# ADSP-2183xW_HPC register map
Vendor: Analog Devices; Series: ADSP-2183xW_HPC; File version: 3.0.3.517
CPU: 
Registers are 32-bit, read-write, reset 0x0 unless marked. A register's access mark holds for its fields unless they carry their own. Offsets are from the block's base; [hi:lo] are bit positions; {n}, {i} and the like mark numbered series; 'fields as' and 'values as' point back to an identical list.

## PFB0 — Prefetch buffer mmr
Base 0x31076000
Same registers: PFB1 0x31145000, PFB2 0x31149000
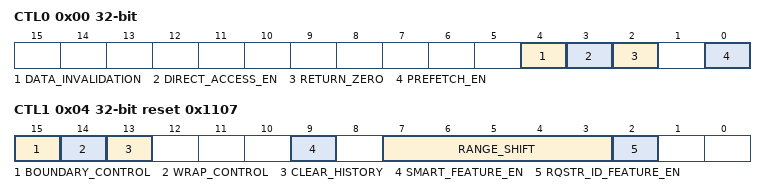
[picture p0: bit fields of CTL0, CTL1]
0x00 CTL0 — Control Register 0
  [4] DATA_INVALIDATION — Data Invalid
  [3] DIRECT_ACCESS_EN — Direct Access Enable
  [2] RETURN_ZERO — Return Zero Data
  [0] PREFETCH_EN — Prefetch Enable
0x04 CTL1 reset 0x1107 — Control Register 1
  [15] BOUNDARY_CONTROL range 0x00000000..0x00000001 — 1: Fetch and Prefetch at 4K boundary crossing control. Configure BCR_START, BCR_END for range. 0: Fetch and Prefetch not at 4k boundary.
  [14] WRAP_CONTROL range 0x00000000..0x00000001 — 1: Direct access for WRAP transaction. 0: normal access
  [13] CLEAR_HISTORY range 0x00000000..0x00000001 — Clear addresses history information in SMART feature
  [9] SMART_FEATURE_EN — Smart Feature Enable
  [7:3] RANGE_SHIFT range 0x00000000..0x0000001F
  [2] RQSTR_ID_FEATURE_EN — ID Based Direct Access Enable
0x14 ZERO_START — Return Zero Start Address Register
  [31:0] VAL range 0x00000000..0xFFFFFFFF — Return Zero Start Address
0x18 ZERO_END — Return Zero End Address Register
  [31:0] VAL range 0x00000000..0xFFFFFFFF — Return Zero End Address
0x1C RANGE_SELECT reset 0xFFFF
  [15:0] VAL range 0x00000000..0x0000FFFF — Range select bit selection
0x20 STS0 reset 0x2 — Prefetch Buffer First Status Register
  [1] PFB_IDLE ro — Prefetch Idle
0x50 RQSTR_ID_EN reset 0xF — Requester ID Enable Register
  [3:0] VAL range 0x00000000..0x0000000F — Requester ID Enable
0x54 RQSTR0_ID reset 0xF — Requester ID 0 Register
  [12:0] VAL range 0x00000000..0x00001FFF — Requester Zero ID
0x58 RQSTR0_ID_MSK — Requester ID 0 Mask Register
  [12:0] VAL range 0x00000000..0x00001FFF — Requester Zero ID Mask
0x5C RQSTR1_ID reset 0xF — Requester ID 1 Register
  [12:0] VAL range 0x00000000..0x00001FFF — Requester One ID
0x60 RQSTR1_ID_MSK — Requester ID 1 Mask Register
  [12:0] VAL range 0x00000000..0x00001FFF — Requester One ID Mask
0x64 RQSTR2_ID reset 0xF — Requester ID 2 Register
  [12:0] VAL range 0x00000000..0x00001FFF — Requester Two ID
0x68 RQSTR2_ID_MSK — Requester ID 2 Mask Register
  [12:0] VAL range 0x00000000..0x00001FFF — Requester Two ID Mask
0x6C RQSTR3_ID reset 0xF — Requester ID 3 Register
  [12:0] VAL range 0x00000000..0x00001FFF — Requester Three ID
0x70 RQSTR3_ID_MSK — Requester ID 3 Mask Register
  [12:0] VAL range 0x00000000..0x00001FFF — Requester Three ID Mask

## L2CTL0 — L2 Memory Controller
Base 0x31080000
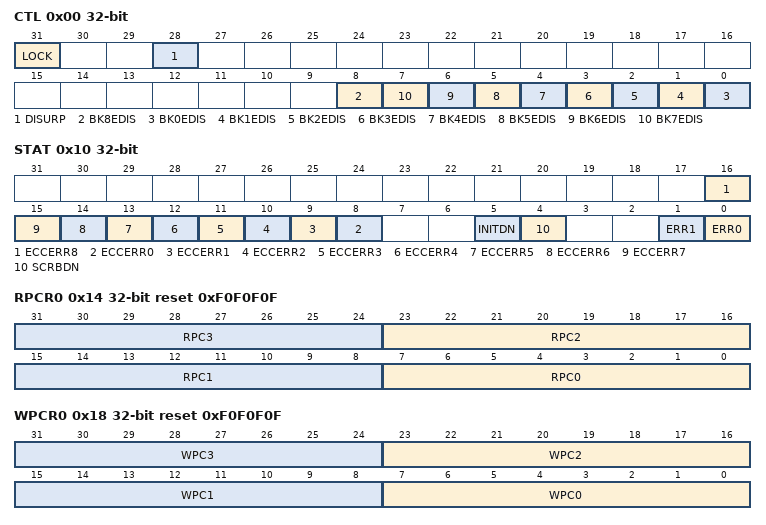
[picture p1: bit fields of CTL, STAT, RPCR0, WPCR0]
0x00 CTL — Control Register
  [31] LOCK
  [28] DISURP — Disable Urgent Request Priority
  [8] BK8EDIS — Bank 8 (ROM) ECC Disable
  [n] BK{n}EDIS (n=0..7) — Bank {n} ECC Disable
0x10 STAT — Status Register
  [16] ECCERR8 — ECC Error Bank 8 (ROM)
  [n+8] ECCERR{n} (n=0..7) — ECC Error Bank {n}
  [5] INITDN — Initialization Status
  [4] SCRBDN — Scrub Status
  [1] ERR1 — Error Port 1
  [0] ERR0 — Error Port 0
0x14 RPCR0 reset 0xF0F0F0F — Read Priority Count Register
  [8n+7:8n] RPC{n} range 0x00000000..0x000000FF (n=0..3) — Read Priority Count {n}
0x18 WPCR0 reset 0xF0F0F0F — Write Priority Count Register
  [8n+7:8n] WPC{n} range 0x00000000..0x000000FF (n=0..3) — Write Priority Count {n}
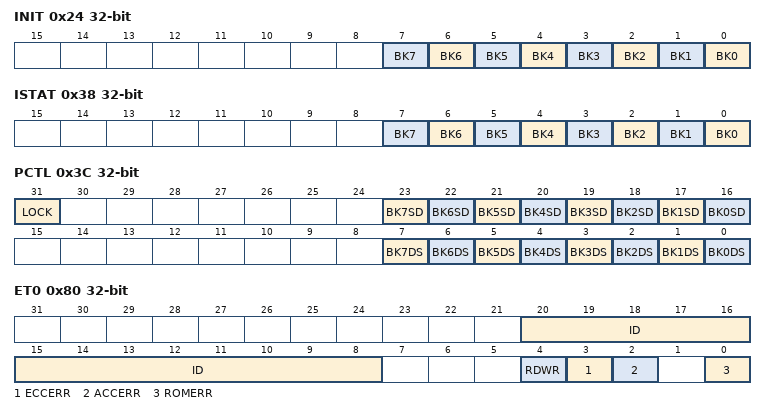
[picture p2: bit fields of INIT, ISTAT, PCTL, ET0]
0x24 INIT — Initialization Register
  [n] BK{n} range 0x00000000..0x00000001 (n=0..7) — Initialize Bank {n}
0x38 ISTAT — Initialization Status Register
  [n] BK{n} ro (n=0..7) — Bank {n} Initialization Status
0x3C PCTL — Power Control Register
  [31] LOCK
  [n+16] BK{n}SD range 0x00000000..0x00000001 (n=0..7) — Bank {n} Shut Down Enable
  [n] BK{n}DS range 0x00000000..0x00000001 (n=0..7) — Bank {n} Deep Sleep Enable
0x40 ERRADDR0 reset 0x20000000 — ECC Error Address 0 Register
  [31:0] VALUE ro — ERRADDR Value
0x44 ERRADDR1 reset 0x20040000 — ECC Error Address 1 Register
  [31:0] VALUE ro — ERRADDR Value
0x48 ERRADDR2 reset 0x20080000 — ECC Error Address 2 Register
  [31:0] VALUE ro — ERRADDR Value
0x4C ERRADDR3 reset 0x200C0000 — ECC Error Address 3 Register
  [31:0] VALUE ro — ERRADDR Value
0x50 ERRADDR4 reset 0x20100000 — ECC Error Address 4 Register
  [31:0] VALUE ro — ERRADDR Value
0x54 ERRADDR5 reset 0x20140000 — ECC Error Address 5 Register
  [31:0] VALUE ro — ERRADDR Value
0x58 ERRADDR6 reset 0x20180000 — ECC Error Address 6 Register
  [31:0] VALUE ro — ERRADDR Value
0x5C ERRADDR7 reset 0x201C0000 — ECC Error Address 7 Register
  [31:0] VALUE ro — ERRADDR Value
0x60 ERRADDR8 reset 0x20200000 — ECC Error Address 8 Register
  [31:0] VALUE ro — ERRADDR Value
0x80 ET0 — Error Type 0 Register
  [20:8] ID ro — Error ID
  [4] RDWR ro — Read/Write Error
  [3] ECCERR ro — ECC Error
  [2] ACCERR ro — Access Error
  [0] ROMERR ro — ROM Error
0x84 EADDR0 — Error Type 0 Address Register
  [31:0] VALUE ro — ERRADDR Value
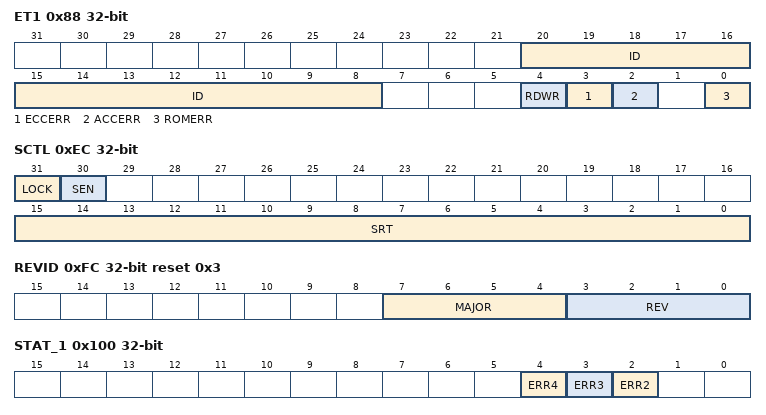
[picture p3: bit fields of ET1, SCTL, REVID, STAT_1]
0x88 ET1 — Error Type 1 Register
  fields as ET0
0x8C EADDR1 — Error Type 1 Address Register
  [31:0] VALUE ro — ERRADDR Value
0xEC SCTL — Scrub Control Register
  [31] LOCK
  [30] SEN range 0x00000000..0x00000001 — Scrub Enable
  [15:0] SRT range 0x00000000..0x0000FFFF — Scrub Rate
0xF0 SADR — Scrub Start Address Register
  [31:0] VALUE range 0x00000000..0xFFFFFFFF — Scrub Start Address
0xF4 SCNT — Scrub Count Register
  [17:0] VALUE range 0x00000000..0x0003FFFF — Scrub Count
0xFC REVID reset 0x3 — Revision ID Register
  [7:4] MAJOR ro — Major ID
  [3:0] REV ro — Revision ID
0x100 STAT_1 — L2 Port Error Status Register
  [4] ERR4 range 0x00000000..0x00000001 — Error Port4
  [3] ERR3 range 0x00000000..0x00000001 — Error Port3
  [2] ERR2 range 0x00000000..0x00000001 — Error Port2
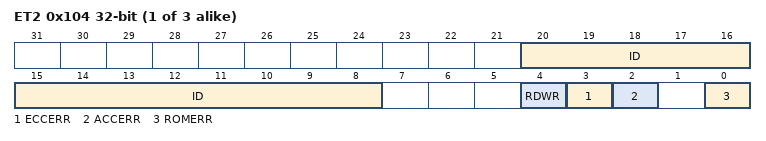
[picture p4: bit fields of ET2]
{0xF4+8i} ET{i} (i=2..4) — Error Type {i} Register
  fields as ET0
{0xF8+8i} EADDR{i} (i=2..4) — Error Type {i} Address Register
  [31:0] VALUE ro — ERRADDR Value
0x130 RPCR1 reset 0xF — Read Priority Count Register
  [7:0] RPC4 range 0x00000000..0x000000FF — Read Priority Count 4
0x134 WPCR1 reset 0xF — Write Priority Count Register
  [7:0] WPC4 range 0x00000000..0x000000FF — Write Priority Count 4
